VERSION ""

NS_ :

BS_:

BU_: XXX

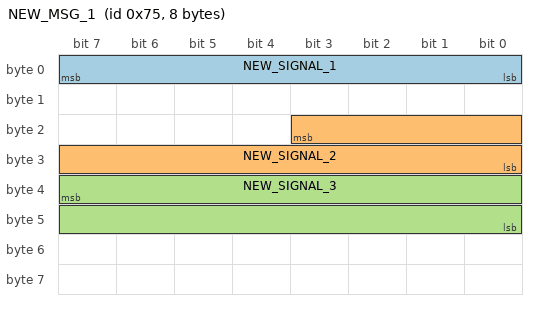
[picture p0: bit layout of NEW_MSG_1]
BO_ 117 NEW_MSG_1: 8 XXX
 SG_ NEW_SIGNAL_1 : 7|8@0+ (1,0) [0|255] "" XXX
 SG_ NEW_SIGNAL_2 : 19|12@0+ (1,0) [0|255] "" XXX
 SG_ NEW_SIGNAL_3 : 39|16@0+ (1,0) [0|131071] "" XXX

BO_ 118 NEW_MSG_2: 8 XXX
 SG_ NEW_SIGNAL_1 : 7|8@0+ (1,0) [0|127] "" XXX
 SG_ NEW_SIGNAL_2 : 19|12@0+ (1,0) [0|4095] "" XXX

BO_ 514 NEW_MSG_3: 8 XXX
 SG_ RPM : 7|16@0+ (1,0) [0|65535] "" XXX
